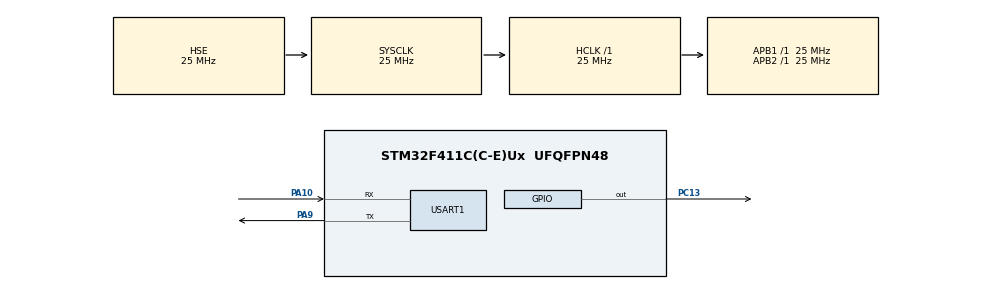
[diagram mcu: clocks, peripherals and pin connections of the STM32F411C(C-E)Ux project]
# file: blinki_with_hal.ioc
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Mcu.Family=STM32F4
Mcu.Name=STM32F411C(C-E)Ux
Mcu.Package=UFQFPN48
NVIC.PriorityGroup=NVIC_PRIORITYGROUP_4
NVIC.TIM2_IRQn=true\:0\:0\:false\:false\:true\:true\:true
NVIC.USART1_IRQn=true\:0\:0\:false\:false\:true\:true\:true
PA10.Mode=Asynchronous
PA10.Signal=USART1_RX
PA9.Mode=Asynchronous
PA9.Signal=USART1_TX
PC13-ANTI_TAMP.PinState=GPIO_PIN_SET
PC13-ANTI_TAMP.Signal=GPIO_Output
PH0\ -\ OSC_IN.Mode=HSE-External-Oscillator
PH0\ -\ OSC_IN.Signal=RCC_OSC_IN
PH1\ -\ OSC_OUT.Mode=HSE-External-Oscillator
PH1\ -\ OSC_OUT.Signal=RCC_OSC_OUT
ProjectManager.HeapSize=0x200
ProjectManager.StackSize=0x400
ProjectManager.TargetToolchain=STM32CubeIDE
RCC.48MHZClocksFreq_Value=48000000
RCC.AHBFreq_Value=25000000
RCC.APB1Freq_Value=25000000
RCC.APB1TimFreq_Value=25000000
RCC.APB2Freq_Value=25000000
RCC.APB2TimFreq_Value=25000000
RCC.CortexFreq_Value=25000000
RCC.HCLKFreq_Value=25000000
RCC.HSE_VALUE=25000000
RCC.HSI_VALUE=16000000
RCC.LSE_VALUE=32768
RCC.SYSCLKFreq_VALUE=25000000
RCC.SYSCLKSource=RCC_SYSCLKSOURCE_HSE
RCC.VCOOutputFreq_Value=192000000
TIM2.Period=500 - 1
TIM2.Prescaler=25000 - 1
USART1.VirtualMode=VM_ASYNC
VP_TIM2_VS_ClockSourceINT.Mode=Internal
board=custom

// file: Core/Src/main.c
/* USER CODE BEGIN Header */
/**
  ******************************************************************************
  * @file           : main.c
  * @brief          : Main program body
  ******************************************************************************
  * @attention
  *
  * <h2><center>&copy; Copyright (c) 2021 STMicroelectronics.
  * All rights reserved.</center></h2>
  *
  * This software component is licensed by ST under BSD 3-Clause license,
  * the "License"; You may not use this file except in compliance with the
  * License. You may obtain a copy of the License at:
  *                        opensource.org/licenses/BSD-3-Clause
  *
  ******************************************************************************
  */
/* USER CODE END Header */
#include "main.h"
#include "task_handler.h"

/* USER CODE BEGIN PD */
#define NUM_OF_BYTES_IN_UINT32 4
/* USER CODE END PD */

TIM_HandleTypeDef htim2;

UART_HandleTypeDef huart1;

/* USER CODE BEGIN PV */
union special_8bit_buff{
	uint32_t total_value;
	uint8_t buff[NUM_OF_BYTES_IN_UINT32];
};

union special_8bit_buff uart_delay_buff;

/* USER CODE END PV */

void SystemClock_Config(void);
static void MX_GPIO_Init(void);
static void MX_TIM2_Init(void);
static void MX_USART1_UART_Init(void);
/* USER CODE BEGIN PFP */
static void TIM2_SetIntervalAndIniUartRead();
static void BLUE_LED_ToggleLED();
/* USER CODE END PFP */

int main(void)
{

  /* MCU Configuration--------------------------------------------------------*/

  /* Reset of all peripherals, Initializes the Flash interface and the Systick. */
  HAL_Init();

  /* Configure the system clock */
  SystemClock_Config();

  /* Initialize all configured peripherals */
  TASK_HANDLER_Init();
  MX_GPIO_Init();
  MX_TIM2_Init();
  MX_USART1_UART_Init();
  /* USER CODE BEGIN 2 */
  HAL_TIM_Base_Start_IT(&htim2);
  HAL_UART_Receive_IT(&huart1, uart_delay_buff.buff, NUM_OF_BYTES_IN_UINT32);

  /* USER CODE END 2 */

  /* Infinite loop */
  while (1)
  {
	  if (TASK_HANDLER_IsTaskWaiting())
	  {
		  task* next_task_fp = TASK_HANDLER_PopNextTask();
		  next_task_fp();
	  }

  }
}

void HAL_UART_RxCpltCallback(UART_HandleTypeDef *huart)
{
	if (huart == &huart1)
	{
		TASK_HANDLER_InsertTask(TIM2_SetIntervalAndIniUartRead);
	}
}

void HAL_TIM_PeriodElapsedCallback(TIM_HandleTypeDef *htim)
{
	if (htim == &htim2)
	{
		TASK_HANDLER_InsertTask(BLUE_LED_ToggleLED);
	}
}
static void BLUE_LED_ToggleLED()
{
	HAL_GPIO_TogglePin(GPIOC, GPIO_PIN_13);
}

static void TIM2_SetIntervalAndIniUartRead()
{
	htim2.Instance->ARR = uart_delay_buff.total_value;
	htim2.Instance->CNT = 0;
	HAL_UART_Receive_IT(&huart1, uart_delay_buff.buff, NUM_OF_BYTES_IN_UINT32);
}

void SystemClock_Config(void)
{
  RCC_OscInitTypeDef RCC_OscInitStruct = {0};
  RCC_ClkInitTypeDef RCC_ClkInitStruct = {0};

  /** Configure the main internal regulator output voltage
  */
  __HAL_RCC_PWR_CLK_ENABLE();
  __HAL_PWR_VOLTAGESCALING_CONFIG(PWR_REGULATOR_VOLTAGE_SCALE1);
  /** Initializes the RCC Oscillators according to the specified parameters
  * in the RCC_OscInitTypeDef structure.
  */
  RCC_OscInitStruct.OscillatorType = RCC_OSCILLATORTYPE_HSE;
  RCC_OscInitStruct.HSEState = RCC_HSE_ON;
  RCC_OscInitStruct.PLL.PLLState = RCC_PLL_NONE;
  if (HAL_RCC_OscConfig(&RCC_OscInitStruct) != HAL_OK)
  {
    Error_Handler();
  }
  /** Initializes the CPU, AHB and APB buses clocks
  */
  RCC_ClkInitStruct.ClockType = RCC_CLOCKTYPE_HCLK|RCC_CLOCKTYPE_SYSCLK
                              |RCC_CLOCKTYPE_PCLK1|RCC_CLOCKTYPE_PCLK2;
  RCC_ClkInitStruct.SYSCLKSource = RCC_SYSCLKSOURCE_HSE;
  RCC_ClkInitStruct.AHBCLKDivider = RCC_SYSCLK_DIV1;
  RCC_ClkInitStruct.APB1CLKDivider = RCC_HCLK_DIV1;
  RCC_ClkInitStruct.APB2CLKDivider = RCC_HCLK_DIV1;

  if (HAL_RCC_ClockConfig(&RCC_ClkInitStruct, FLASH_LATENCY_0) != HAL_OK)
  {
    Error_Handler();
  }
}

static void MX_TIM2_Init(void)
{

  TIM_ClockConfigTypeDef sClockSourceConfig = {0};
  TIM_MasterConfigTypeDef sMasterConfig = {0};

  htim2.Instance = TIM2;
  htim2.Init.Prescaler = 25000 - 1;
  htim2.Init.CounterMode = TIM_COUNTERMODE_UP;
  htim2.Init.Period = 500 - 1;
  htim2.Init.ClockDivision = TIM_CLOCKDIVISION_DIV1;
  htim2.Init.AutoReloadPreload = TIM_AUTORELOAD_PRELOAD_DISABLE;
  if (HAL_TIM_Base_Init(&htim2) != HAL_OK)
  {
    Error_Handler();
  }
  sClockSourceConfig.ClockSource = TIM_CLOCKSOURCE_INTERNAL;
  if (HAL_TIM_ConfigClockSource(&htim2, &sClockSourceConfig) != HAL_OK)
  {
    Error_Handler();
  }
  sMasterConfig.MasterOutputTrigger = TIM_TRGO_RESET;
  sMasterConfig.MasterSlaveMode = TIM_MASTERSLAVEMODE_DISABLE;
  if (HAL_TIMEx_MasterConfigSynchronization(&htim2, &sMasterConfig) != HAL_OK)
  {
    Error_Handler();
  }

}

static void MX_USART1_UART_Init(void)
{

  huart1.Instance = USART1;
  huart1.Init.BaudRate = 115200;
  huart1.Init.WordLength = UART_WORDLENGTH_8B;
  huart1.Init.StopBits = UART_STOPBITS_1;
  huart1.Init.Parity = UART_PARITY_NONE;
  huart1.Init.Mode = UART_MODE_TX_RX;
  huart1.Init.HwFlowCtl = UART_HWCONTROL_NONE;
  huart1.Init.OverSampling = UART_OVERSAMPLING_16;
  if (HAL_UART_Init(&huart1) != HAL_OK)
  {
    Error_Handler();
  }

}

static void MX_GPIO_Init(void)
{
  GPIO_InitTypeDef GPIO_InitStruct = {0};

  /* GPIO Ports Clock Enable */
  __HAL_RCC_GPIOC_CLK_ENABLE();
  __HAL_RCC_GPIOH_CLK_ENABLE();
  __HAL_RCC_GPIOA_CLK_ENABLE();

  /*Configure GPIO pin Output Level */
  HAL_GPIO_WritePin(GPIOC, GPIO_PIN_13, GPIO_PIN_SET);

  /*Configure GPIO pin : PC13 */
  GPIO_InitStruct.Pin = GPIO_PIN_13;
  GPIO_InitStruct.Mode = GPIO_MODE_OUTPUT_PP;
  GPIO_InitStruct.Pull = GPIO_NOPULL;
  GPIO_InitStruct.Speed = GPIO_SPEED_FREQ_LOW;
  HAL_GPIO_Init(GPIOC, &GPIO_InitStruct);

}

void Error_Handler(void)
{
  __disable_irq();
  while (1)
  {
  }
}

/************************ (C) COPYRIGHT STMicroelectronics *****END OF FILE****/
